# PIC18F46Q10 register map
Vendor: Microchip
Registers are 8-bit, read-write, reset 0x0 unless marked. A register's access mark holds for its fields unless they carry their own. Addresses are absolute, and some are shared; only a register's first bit layout is shown; [hi:lo] are bit positions; {n}, {i} and the like mark numbered series; 'fields as' and 'values as' point back to an identical list.

## dac_nbit_ctrl
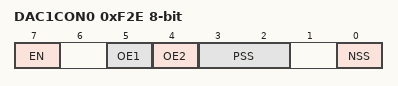
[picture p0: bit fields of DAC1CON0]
0xF2E DAC1CON0
  [7] EN, [5] OE1, [4] OE2, [3:2] PSS, [0] NSS
0xF2F DAC1CON1 reset not defined — (power-on value ---xxxxx)
  [4:0] DAC1R

## cmp_rr_ctrl
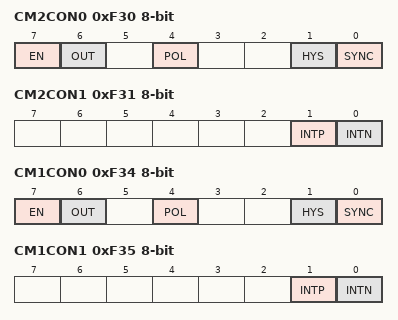
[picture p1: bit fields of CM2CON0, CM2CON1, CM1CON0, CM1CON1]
0xF30 CM2CON0 — COMPARATOR CONTROL REGISTER 0
  [7] EN — Comparator Enable bit
  [6] OUT ro — Comparator Output bit
  [4] POL — Comparator Output Polarity Select bit
  [1] HYS — Comparator Hysteresis Enable bit
  [0] SYNC — Comparator Output Synchronous Mode bit
0xF31 CM2CON1 — COMPARATOR CONTROL REGISTER 1
  [1] INTP — Comparator Interrupt on Positive going edge Enable bits
  [0] INTN — Comparator Interrupt on Negative going edge Enable bits
0xF32 CM2NCH — COMPARATOR INVERTING CHANNEL SELECT REGISTER
  [2:0] NCH — Comparator Inverting Input Channel Select bits
0xF33 CM2PCH — COMPARATOR NON-INVERTING CHANNEL SELECT REGISTER
  [2:0] PCH — Comparator Non-Inverting Input Channel Select bits
0xF34 CM1CON0 — COMPARATOR CONTROL REGISTER 0
  fields as CM2CON0
0xF35 CM1CON1 — COMPARATOR CONTROL REGISTER 1
  fields as CM2CON1
0xF36 CM1NCH — COMPARATOR INVERTING CHANNEL SELECT REGISTER
  [2:0] NCH — Comparator Inverting Input Channel Select bits
0xF37 CM1PCH — COMPARATOR NON-INVERTING CHANNEL SELECT REGISTER
  [2:0] PCH — Comparator Non-Inverting Input Channel Select bits

## wg_cwg
0xF3B CWG1CLK
  [0] CS
0xF3C CWG1ISM
  [4:0] IS
0xF3D CWG1DBR
  [5:0] DBR
0xF3E CWG1DBF
  [5:0] DBF
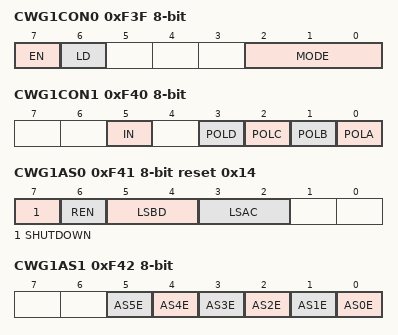
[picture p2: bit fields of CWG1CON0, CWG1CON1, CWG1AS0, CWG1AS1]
0xF3F CWG1CON0
  [7] EN, [6] LD, [2:0] MODE
0xF40 CWG1CON1 reset not defined — (power-on value --x-0000)
  [5] IN ro, [3] POLD, [2] POLC, [1] POLB, [0] POLA
0xF41 CWG1AS0 reset 0x14
  [7] SHUTDOWN, [6] REN, [5:4] LSBD, [3:2] LSAC
0xF42 CWG1AS1
  [n] AS{n}E (n=0..5)
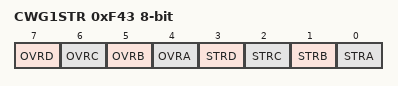
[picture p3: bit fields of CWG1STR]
0xF43 CWG1STR
  [7] OVRD, [6] OVRC, [5] OVRB, [4] OVRA, [3] STRD, [2] STRC, [1] STRB, [0] STRA

## dma_nvm
0xF44 SCANLADRL
  [7:0] LADR
0xF45 SCANLADRH
  [7:0] LADR
0xF46 SCANLADRU
  [5:0] LADR
0xF47 SCANHADRL reset 0xFF
  [7:0] HADR
0xF48 SCANHADRH reset 0xFF
  [7:0] HADR
0xF49 SCANHADRU reset 0x3F
  [5:0] HADR
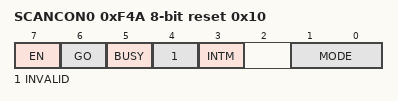
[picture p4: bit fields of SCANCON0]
0xF4A SCANCON0 reset 0x10
  [7] EN, [6] GO, [5] BUSY ro, [4] INVALID ro, [3] INTM, [1:0] MODE
0xF4B SCANTRIG
  [3:0] TSEL

## txm_mod
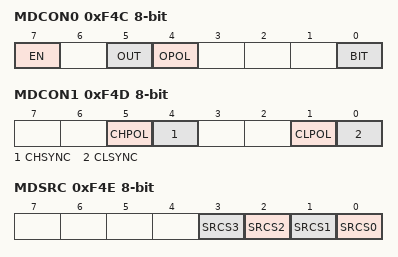
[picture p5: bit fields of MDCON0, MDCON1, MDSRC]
0xF4C MDCON0
  [7] EN, [5] OUT, [4] OPOL, [0] BIT
0xF4D MDCON1
  [5] CHPOL, [4] CHSYNC, [1] CLPOL, [0] CLSYNC
0xF4E MDSRC
  [n] SRCS{n} (n=0..3)
0xF4F MDCARL
  [2:0] CLS
0xF50 MDCARH
  [2:0] CHS

## adc_sarcore_mp_ctrl
0xF51 ADACT
  [4:0] ADACT
0xF52 ADCLK
  [5:0] ADCS
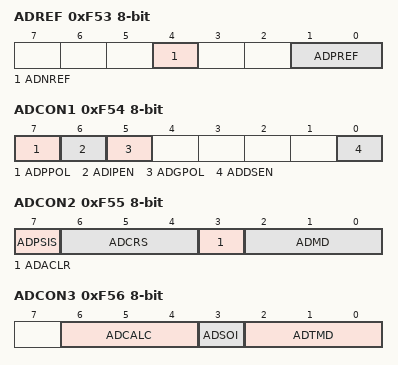
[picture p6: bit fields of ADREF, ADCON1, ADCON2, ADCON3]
0xF53 ADREF
  [4] ADNREF, [1:0] ADPREF
0xF54 ADCON1
  [7] ADPPOL, [6] ADIPEN, [5] ADGPOL, [0] ADDSEN
0xF55 ADCON2
  [7] ADPSIS, [6:4] ADCRS, [3] ADACLR, [2:0] ADMD
0xF56 ADCON3
  [6:4] ADCALC, [3] ADSOI, [2:0] ADTMD
0xF57 ADACQ
0xF58 ADCAP
  [4:0] ADCAP
0xF59 ADPRE
0xF5A ADPCH
  [5:0] ADPCH
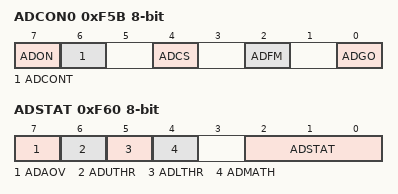
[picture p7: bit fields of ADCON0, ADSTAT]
0xF5B ADCON0
  [7] ADON, [6] ADCONT, [4] ADCS, [2] ADFM, [0] ADGO
0xF5C ADPREVL ro
0xF5D ADPREVH ro
0xF5E ADRESL
0xF5F ADRESH
0xF60 ADSTAT
  [7] ADAOV, [6] ADUTHR ro, [5] ADLTHR ro, [4] ADMATH ro, [2:0] ADSTAT ro
0xF61 ADRPT
0xF62 ADCNT
0xF63 ADSTPTL
0xF64 ADSTPTH
0xF65 ADLTHL
0xF66 ADLTHH
0xF67 ADUTHL
0xF68 ADUTHH
0xF69 ADERRL ro
0xF6A ADERRH ro
0xF6B ADACCL reset not defined — (power-on value xxxxxxxx)
0xF6C ADACCH reset not defined — (power-on value xxxxxxxx)
0xF6D ADFLTRL ro reset not defined — (power-on value xxxxxxxx)
0xF6E ADFLTRH ro reset not defined — (power-on value xxxxxxxx)

## math_progcrc
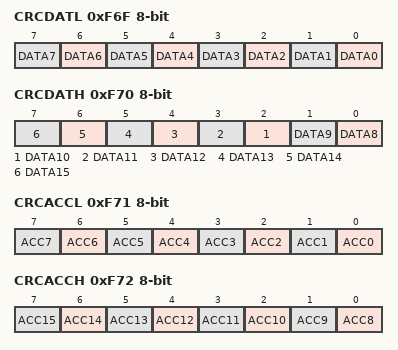
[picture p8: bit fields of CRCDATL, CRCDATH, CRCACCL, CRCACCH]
0xF6F CRCDATL reset not defined — (power-on value xxxxxxxx)
  [n] DATA{n} (n=0..7)
0xF70 CRCDATH reset not defined — (power-on value xxxxxxxx)
  [n-8] DATA{n} (n=8..15)
0xF71 CRCACCL
  [n] ACC{n} (n=0..7)
0xF72 CRCACCH
  [n-8] ACC{n} (n=8..15)
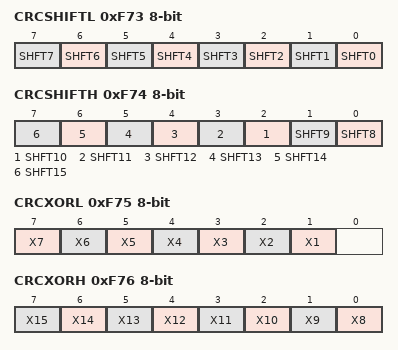
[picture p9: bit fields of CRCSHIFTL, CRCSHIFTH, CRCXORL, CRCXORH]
0xF73 CRCSHIFTL ro
  [n] SHFT{n} (n=0..7)
0xF74 CRCSHIFTH ro
  [n-8] SHFT{n} (n=8..15)
0xF75 CRCXORL reset not defined — (power-on value xxxxxxx1)
  [n] X{n} (n=1..7)
0xF76 CRCXORH reset not defined — (power-on value xxxxxxxx)
  [n-8] X{n} (n=8..15)
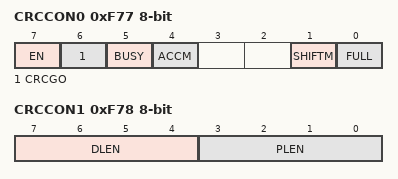
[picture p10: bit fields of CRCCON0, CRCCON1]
0xF77 CRCCON0
  [7] EN, [6] CRCGO, [5] BUSY ro, [4] ACCM, [1] SHIFTM, [0] FULL ro
0xF78 CRCCON1
  [7:4] DLEN, [3:0] PLEN

## pwm
0xF9F PWM4DCL reset not defined — (power-on value xx------)
  [7:6] DC
0xFA0 PWM4DCH reset not defined — (power-on value xxxxxxxx)
  [7:0] DC
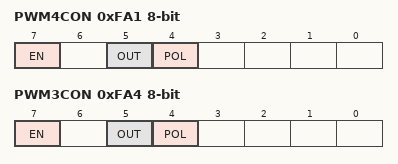
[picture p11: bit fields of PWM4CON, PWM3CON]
0xFA1 PWM4CON
  [7] EN, [5] OUT ro, [4] POL
0xFA2 PWM3DCL reset not defined — (power-on value xx------)
  [7:6] DC
0xFA3 PWM3DCH reset not defined — (power-on value xxxxxxxx)
  [7:0] DC
0xFA4 PWM3CON
  [7] EN, [5] OUT ro, [4] POL

## ccp
0xFA5 CCPR2L reset not defined — (power-on value xxxxxxxx)
  [7:0] RL
0xFA6 CCPR2H reset not defined — (power-on value xxxxxxxx)
  [7:0] RH
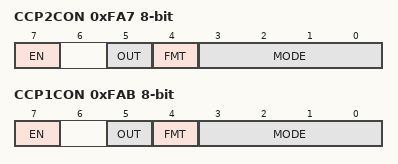
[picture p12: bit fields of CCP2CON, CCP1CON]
0xFA7 CCP2CON
  [7] EN, [5] OUT ro, [4] FMT, [3:0] MODE
0xFA8 CCP2CAP
  [1:0] CTS
0xFA9 CCPR1L reset not defined — (power-on value xxxxxxxx)
  [7:0] RL
0xFAA CCPR1H reset not defined — (power-on value xxxxxxxx)
  [7:0] RH
0xFAB CCP1CON
  [7] EN, [5] OUT ro, [4] FMT, [3:0] MODE
0xFAC CCP1CAP
  [1:0] CTS

## tmr
0xFAE T6TMR — 8-bit period timer
  [7:0] TMR6
0xFAF T6PR reset 0xFF
  [7:0] PR6
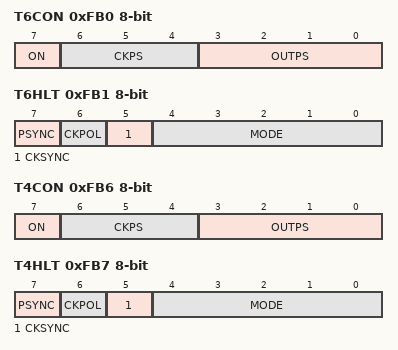
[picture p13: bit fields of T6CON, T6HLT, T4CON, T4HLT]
0xFB0 T6CON
  [7] ON, [6:4] CKPS, [3:0] OUTPS
0xFB1 T6HLT
  [7] PSYNC, [6] CKPOL, [5] CKSYNC, [4:0] MODE
0xFB2 T6CLKCON
  [3:0] CS
0xFB3 T6RST
  [4:0] RSEL
0xFB4 T4TMR — 8-bit period timer
  [7:0] TMR4
0xFB5 T4PR reset 0xFF
  [7:0] PR4
0xFB6 T4CON
  [7] ON, [6:4] CKPS, [3:0] OUTPS
0xFB7 T4HLT
  [7] PSYNC, [6] CKPOL, [5] CKSYNC, [4:0] MODE
0xFB8 T4CLKCON
  [3:0] CS
0xFB9 T4RST
  [4:0] RSEL
0xFBA T2TMR — 8-bit period timer
  [7:0] TMR2
0xFBB T2PR reset 0xFF
  [7:0] PR2
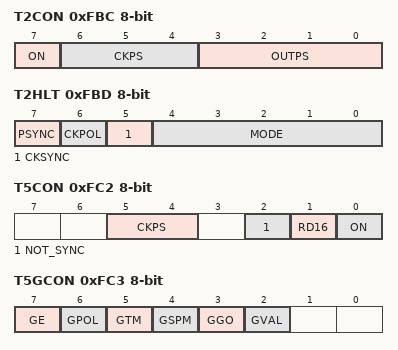
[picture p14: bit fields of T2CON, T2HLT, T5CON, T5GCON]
0xFBC T2CON
  [7] ON, [6:4] CKPS, [3:0] OUTPS
0xFBD T2HLT
  [7] PSYNC, [6] CKPOL, [5] CKSYNC, [4:0] MODE
0xFBE T2CLKCON
  [3:0] CS
0xFBF T2RST
  [4:0] RSEL
0xFC0 TMR5L
0xFC1 TMR5H
0xFC2 T5CON
  [5:4] CKPS, [2] NOT_SYNC, [1] RD16, [0] ON
0xFC3 T5GCON reset not defined — (power-on value 00000x--)
  [7] GE, [6] GPOL, [5] GTM, [4] GSPM, [3] GGO, [2] GVAL ro
0xFC4 T5GATE
  [4:0] GSS
0xFC5 T5CLK
  [4:0] CS
0xFC6 TMR3L
0xFC7 TMR3H
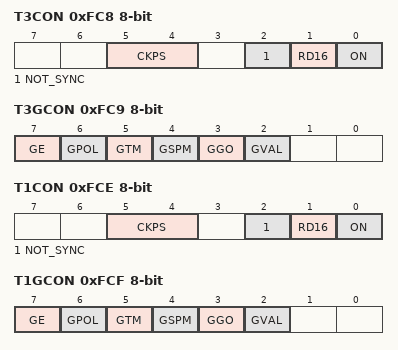
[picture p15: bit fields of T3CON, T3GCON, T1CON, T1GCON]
0xFC8 T3CON
  [5:4] CKPS, [2] NOT_SYNC, [1] RD16, [0] ON
0xFC9 T3GCON reset not defined — (power-on value 00000x--)
  [7] GE, [6] GPOL, [5] GTM, [4] GSPM, [3] GGO, [2] GVAL ro
0xFCA T3GATE
  [4:0] GSS
0xFCB T3CLK
  [4:0] CS
0xFCC TMR1L
0xFCD TMR1H
0xFCE T1CON
  [5:4] CKPS, [2] NOT_SYNC, [1] RD16, [0] ON
0xFCF T1GCON reset not defined — (power-on value 00000x--)
  [7] GE, [6] GPOL, [5] GTM, [4] GSPM, [3] GGO, [2] GVAL ro
0xFD0 T1GATE
  [4:0] GSS
0xFD1 T1CLK
  [4:0] CS
0xFD2 TMR0L
0xFD3 TMR0H reset 0xFF
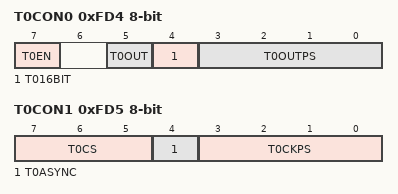
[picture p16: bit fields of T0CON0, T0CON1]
0xFD4 T0CON0
  [7] T0EN, [5] T0OUT ro, [4] T016BIT, [3:0] T0OUTPS
0xFD5 T0CON1
  [7:5] T0CS, [4] T0ASYNC, [3:0] T0CKPS
